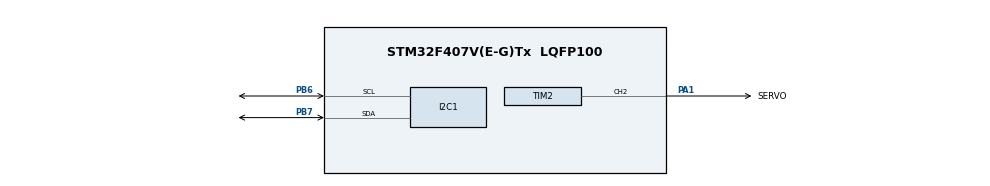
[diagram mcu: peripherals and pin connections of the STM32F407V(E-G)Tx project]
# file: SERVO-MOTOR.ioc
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I2C1.I2C_Mode=I2C_Standard
Mcu.Family=STM32F4
Mcu.Name=STM32F407V(E-G)Tx
Mcu.Package=LQFP100
NVIC.PriorityGroup=NVIC_PRIORITYGROUP_4
PA1.GPIO_Label=SERVO
PA1.Signal=S_TIM2_CH2
PA13.Mode=Serial_Wire
PA13.Signal=SYS_JTMS-SWDIO
PA14.Mode=Serial_Wire
PA14.Signal=SYS_JTCK-SWCLK
PB6.Mode=I2C
PB6.Signal=I2C1_SCL
PB7.Mode=I2C
PB7.Signal=I2C1_SDA
PH0-OSC_IN.Mode=HSE-External-Oscillator
PH0-OSC_IN.Signal=RCC_OSC_IN
PH1-OSC_OUT.Mode=HSE-External-Oscillator
PH1-OSC_OUT.Signal=RCC_OSC_OUT
ProjectManager.HeapSize=0x200
ProjectManager.StackSize=0x400
ProjectManager.TargetToolchain=STM32CubeIDE
RCC.48MHZClocksFreq_Value=36000000
RCC.AHBFreq_Value=72000000
RCC.APB1CLKDivider=RCC_HCLK_DIV2
RCC.APB1Freq_Value=36000000
RCC.APB1TimFreq_Value=72000000
RCC.APB2Freq_Value=72000000
RCC.APB2TimFreq_Value=72000000
RCC.CortexFreq_Value=72000000
RCC.HCLKFreq_Value=72000000
RCC.HSE_VALUE=8000000
RCC.HSI_VALUE=16000000
RCC.LSE_VALUE=32768
RCC.PLLM=8
RCC.PLLN=72
RCC.SYSCLKFreq_VALUE=72000000
RCC.SYSCLKSource=RCC_SYSCLKSOURCE_PLLCLK
RCC.VCOOutputFreq_Value=144000000
SH.S_TIM2_CH2.0=TIM2_CH2,PWM Generation2 CH2
TIM2.AutoReloadPreload=TIM_AUTORELOAD_PRELOAD_ENABLE
TIM2.Channel-PWM\ Generation2\ CH2=TIM_CHANNEL_2
TIM2.Period=0xFFFF-1
TIM2.Prescaler=71
VP_TIM2_VS_ClockSourceINT.Mode=Internal
board=custom

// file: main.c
/* USER CODE END Header */
#include "main.h"

/* USER CODE BEGIN Includes */
#include "stdio.h"
#include "SERVO-MOTOR.h"
#include "LCD_I2C.h"
/* USER CODE END Includes */

/* USER CODE BEGIN PD */
char buffer[20];
Servo_HandleTypeDef my_servo;
int angle;
/* USER CODE END PD */

I2C_HandleTypeDef hi2c1;
TIM_HandleTypeDef htim2;

void SystemClock_Config(void);
static void MX_GPIO_Init(void);
static void MX_I2C1_Init(void);
static void MX_TIM2_Init(void);

int main(void)
{

  /* MCU Configuration--------------------------------------------------------*/

  /* Reset of all peripherals, Initializes the Flash interface and the Systick. */
  HAL_Init();

  /* Configure the system clock */
  SystemClock_Config();

  /* Initialize all configured peripherals */
  MX_GPIO_Init();
  MX_I2C1_Init();
  MX_TIM2_Init();
  /* USER CODE BEGIN 2 */
  LCD_INIT();
  SERVO_INIT(&my_servo, &htim2, TIM_CHANNEL_2, 500, 2500, 0, 180);
  LCD_SET_CURSOR(0, 0);
  LCD_SEND_STRING(".. Servo Motor ..");
  /* USER CODE END 2 */

  /* Infinite loop */
  /* USER CODE BEGIN WHILE */
  while (1)
  {
	  for (angle = 0; angle <= 180; angle += 10)
	  {
  		SERVO_SETANGLE(&my_servo, angle);
  		snprintf(buffer, sizeof(buffer), "Angle : %4d", angle);
  		LCD_SET_CURSOR(1, 0);
  		LCD_SEND_STRING(buffer);
  		HAL_Delay(200);
	  }

	  for (angle = 180; angle >= 0; angle -= 10)
	  {
  		SERVO_SETANGLE(&my_servo, angle);
  		snprintf(buffer, sizeof(buffer), "Angle : %4d", angle);
  		LCD_SET_CURSOR(1, 0);
  		LCD_SEND_STRING(buffer);
  		HAL_Delay(200);
	  }
    /* USER CODE END WHILE */

  }
}
